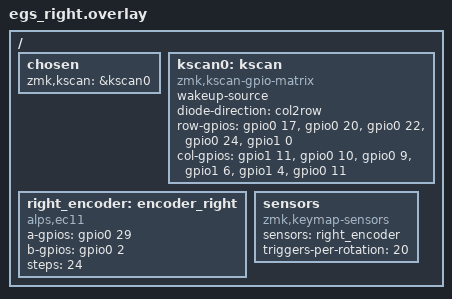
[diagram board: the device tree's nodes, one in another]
/*
 * Copyright (c) 2026 The EGS_W1 Project Contributor
 * SPDX-License-Identifier: MIT
 */

#include "egs.dtsi"

/ {
    chosen {
        zmk,kscan = &kscan0;
    };

    kscan0: kscan {
        compatible = "zmk,kscan-gpio-matrix";
        wakeup-source;
        diode-direction = "col2row";

        // Right Side Row GPIO Pins
        row-gpios
            = <&gpio0 17 (GPIO_ACTIVE_HIGH | GPIO_PULL_DOWN)>  // Row 0 -> D2 (P0.17)
            , <&gpio0 20 (GPIO_ACTIVE_HIGH | GPIO_PULL_DOWN)>  // Row 1 -> D3 (P0.20)
            , <&gpio0 22 (GPIO_ACTIVE_HIGH | GPIO_PULL_DOWN)>  // Row 2 -> D4 (P0.22)
            , <&gpio0 24 (GPIO_ACTIVE_HIGH | GPIO_PULL_DOWN)>  // Row 3 -> D5 (P0.24)
            , <&gpio1 0 (GPIO_ACTIVE_HIGH | GPIO_PULL_DOWN)>  // Row 4 -> D6 (P1.00)
            ;

        // Right Side Column GPIO Pins
        col-gpios
            = <&gpio1 11 (GPIO_ACTIVE_HIGH)>  // Col 0 -> D7  (P1.11)
            , <&gpio0 10 (GPIO_ACTIVE_HIGH)>  // Col 1 -> D8  (P0.10)
            , <&gpio0 9 (GPIO_ACTIVE_HIGH)>  // Col 2 -> D9  (P0.09)
            , <&gpio1 6 (GPIO_ACTIVE_HIGH)>  // Col 3 -> D10 (P1.06)
            , <&gpio1 4 (GPIO_ACTIVE_HIGH)>  // Col 4 -> D16 (P1.04)
            , <&gpio0 11 (GPIO_ACTIVE_HIGH)>  // Col 5 -> D14 (P0.11)
            ;
    };

    // Right Side Media Navigation Encoder Hardware Profile
    right_encoder: encoder_right {
        compatible = "alps,ec11";
        a-gpios = <&gpio0 29 (GPIO_ACTIVE_HIGH | GPIO_PULL_UP)>; // Pin 18 (P0.29)
        b-gpios = <&gpio0 2 (GPIO_ACTIVE_HIGH | GPIO_PULL_UP)>; // Pin 19 (P0.02)
        steps = <24>;
    };

    sensors: sensors {
        compatible = "zmk,keymap-sensors";
        sensors = <&right_encoder>;
        triggers-per-rotation = <20>;
    };
};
